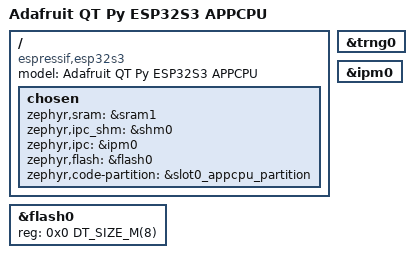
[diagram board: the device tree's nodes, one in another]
/*
 * Copyright (c) 2024 Ian Wakely
 *
 * SPDX-License-Identifier: Apache-2.0
 */

/dts-v1/;

#include <espressif/esp32s3/esp32s3.dtsi>
#include "adafruit_qt_py_esp32s3-pinctrl.dtsi"
#include <espressif/partitions_0x0_amp.dtsi>

/ {
	model = "Adafruit QT Py ESP32S3 APPCPU";
	compatible = "espressif,esp32s3";

	chosen {
		zephyr,sram = &sram1;
		zephyr,ipc_shm = &shm0;
		zephyr,ipc = &ipm0;
		zephyr,flash = &flash0;
		zephyr,code-partition = &slot0_appcpu_partition;
	};
};

&flash0 {
	reg = <0x0 DT_SIZE_M(8)>;
	ranges = <0x0 0x0 DT_SIZE_M(8)>;
};

&trng0 {
	status = "okay";
};

&ipm0 {
	status = "okay";
};
